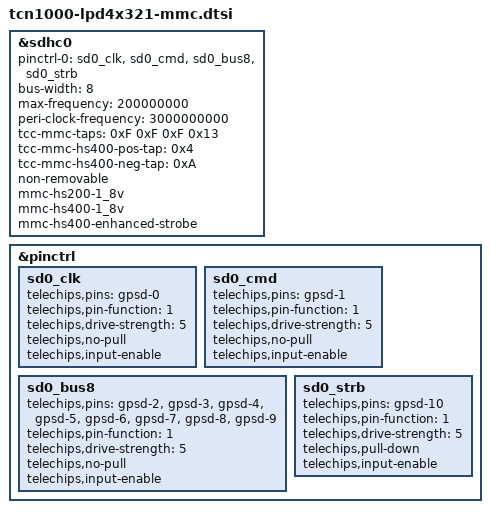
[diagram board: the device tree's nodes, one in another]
// SPDX-License-Identifier: (GPL-2.0-or-later OR MIT)
/*
 * Copyright (C) 2023 Telechips Inc.
 */

/* eMMC */
&sdhc0 {
	pinctrl-names = "default";
	pinctrl-0 = <&sd0_clk>, <&sd0_cmd>, <&sd0_bus8>, <&sd0_strb>;
	bus-width = <8>;
	status = "okay";
	max-frequency = <200000000>;
	peri-clock-frequency = <3000000000>;

	tcc-mmc-taps = <0xF 0xF 0xF 0x13>;
	tcc-mmc-hs400-pos-tap = <0x4>;
	tcc-mmc-hs400-neg-tap = <0xA>;

	non-removable;
	mmc-hs200-1_8v;
	mmc-hs400-1_8v;
	mmc-hs400-enhanced-strobe;
};

&pinctrl {
	/omit-if-no-ref/
	sd0_clk: sd0_clk {
		telechips,pins = "gpsd-0";
		telechips,pin-function = <1>;
		telechips,drive-strength = <5>;
		telechips,no-pull;
		telechips,input-enable;
	};

	/omit-if-no-ref/
	sd0_cmd: sd0_cmd {
		telechips,pins = "gpsd-1";
		telechips,pin-function = <1>;
		telechips,drive-strength = <5>;
		telechips,no-pull;
		telechips,input-enable;
	};

	/omit-if-no-ref/
	sd0_bus8: sd0_bus8 {
		telechips,pins =  "gpsd-2", "gpsd-3", "gpsd-4", "gpsd-5",
		                  "gpsd-6", "gpsd-7", "gpsd-8", "gpsd-9";
		telechips,pin-function = <1>;
		telechips,drive-strength = <5>;
		telechips,no-pull;
		telechips,input-enable;
	};

	/omit-if-no-ref/
	sd0_strb: sd0_strb {
		telechips,pins = "gpsd-10";
		telechips,pin-function = <1>;
		telechips,drive-strength = <5>;
		telechips,pull-down;
		telechips,input-enable;
	};
};

